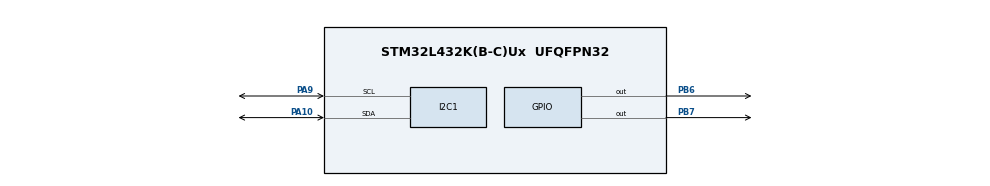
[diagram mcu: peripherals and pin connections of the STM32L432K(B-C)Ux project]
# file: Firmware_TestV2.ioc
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Mcu.Family=STM32L4
Mcu.Name=STM32L432K(B-C)Ux
Mcu.Package=UFQFPN32
NVIC.PriorityGroup=NVIC_PRIORITYGROUP_4
NVIC.TIM6_DAC_IRQn=true\:0\:0\:false\:false\:true\:true\:true
PA10.Mode=I2C
PA10.Signal=I2C1_SDA
PA13\ (JTMS-SWDIO).Mode=Trace_Asynchronous_SW
PA13\ (JTMS-SWDIO).Signal=SYS_JTMS-SWDIO
PA14\ (JTCK-SWCLK).Mode=Trace_Asynchronous_SW
PA14\ (JTCK-SWCLK).Signal=SYS_JTCK-SWCLK
PA9.Mode=I2C
PA9.Signal=I2C1_SCL
PB3\ (JTDO-TRACESWO).Mode=Trace_Asynchronous_SW
PB3\ (JTDO-TRACESWO).Signal=SYS_JTDO-SWO
PB6.Signal=GPIO_Output
PB7.Signal=GPIO_Output
ProjectManager.HeapSize=0x200
ProjectManager.StackSize=0x400
ProjectManager.TargetToolchain=STM32CubeIDE
RCC.HSE_VALUE=8000000
RCC.HSI48_VALUE=48000000
RCC.HSI_VALUE=16000000
RCC.LSE_VALUE=32768
RCC.MSI_VALUE=4000000
RCC.VCOOutputFreq_Value=32000000
TIM6.Period=5000-1
TIM6.Prescaler=800-1
VP_TIM6_VS_ClockSourceINT.Mode=Enable_Timer
board=custom

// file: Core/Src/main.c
/* USER CODE BEGIN Header */
/**
  ******************************************************************************
  * @file           : main.c
  * @brief          : Main program body
  ******************************************************************************
  * @attention
  *
  * <h2><center>&copy; Copyright (c) 2021 STMicroelectronics.
  * All rights reserved.</center></h2>
  *
  * This software component is licensed by ST under BSD 3-Clause license,
  * the "License"; You may not use this file except in compliance with the
  * License. You may obtain a copy of the License at:
  *                        opensource.org/licenses/BSD-3-Clause
  *
  ******************************************************************************
  */
/* USER CODE END Header */
#include "main.h"

/* USER CODE BEGIN Includes */
#include "math.h"
#include "BQ76930.h"
//#include "bq76930_func.h"
//#include "registers.h"
/* USER CODE END Includes */

/* USER CODE BEGIN PD */
void readADCGAIN();
void readVoltage();
/* USER CODE END PD */

I2C_HandleTypeDef hi2c1;	// STM HAL I2C handler
TIM_HandleTypeDef htim6;	// STM HAL timer handler

void SystemClock_Config(void);
static void MX_GPIO_Init(void);
static void MX_I2C1_Init(void);
static void MX_TIM6_Init(void);

int main(void)
{
  /* USER CODE BEGIN 1 */
	HAL_StatusTypeDef ret;
  /* USER CODE END 1 */

  /* MCU Configuration--------------------------------------------------------*/

  /* Reset of all peripherals, Initializes the Flash interface and the Systick. */
  HAL_Init();

  /* USER CODE BEGIN Init */
  uint8_t data;
  /* USER CODE END Init */

  /* Configure the system clock */
  SystemClock_Config();

  /* Initialize all configured peripherals */
  MX_GPIO_Init();
  MX_I2C1_Init();
  MX_TIM6_Init();
  /* USER CODE BEGIN 2 */
  HAL_TIM_Base_Start_IT(&htim6);	//start timer
  LVBatLiPo dev;

  BQ76930_Initialise(&dev, &hi2c1);	//init device

  /* USER CODE END 2 */

  /* Infinite loop */
  while (1)
  {

  }
}

void SystemClock_Config(void)
{
  RCC_OscInitTypeDef RCC_OscInitStruct = {0};
  RCC_ClkInitTypeDef RCC_ClkInitStruct = {0};
  RCC_PeriphCLKInitTypeDef PeriphClkInit = {0};

  /** Initializes the RCC Oscillators according to the specified parameters
  * in the RCC_OscInitTypeDef structure.
  */
  RCC_OscInitStruct.OscillatorType = RCC_OSCILLATORTYPE_MSI;
  RCC_OscInitStruct.MSIState = RCC_MSI_ON;
  RCC_OscInitStruct.MSICalibrationValue = 0;
  RCC_OscInitStruct.MSIClockRange = RCC_MSIRANGE_6;
  RCC_OscInitStruct.PLL.PLLState = RCC_PLL_NONE;
  if (HAL_RCC_OscConfig(&RCC_OscInitStruct) != HAL_OK)
  {
    Error_Handler();
  }
  /** Initializes the CPU, AHB and APB buses clocks
  */
  RCC_ClkInitStruct.ClockType = RCC_CLOCKTYPE_HCLK|RCC_CLOCKTYPE_SYSCLK
                              |RCC_CLOCKTYPE_PCLK1|RCC_CLOCKTYPE_PCLK2;
  RCC_ClkInitStruct.SYSCLKSource = RCC_SYSCLKSOURCE_MSI;
  RCC_ClkInitStruct.AHBCLKDivider = RCC_SYSCLK_DIV1;
  RCC_ClkInitStruct.APB1CLKDivider = RCC_HCLK_DIV1;
  RCC_ClkInitStruct.APB2CLKDivider = RCC_HCLK_DIV1;

  if (HAL_RCC_ClockConfig(&RCC_ClkInitStruct, FLASH_LATENCY_0) != HAL_OK)
  {
    Error_Handler();
  }
  PeriphClkInit.PeriphClockSelection = RCC_PERIPHCLK_I2C1;
  PeriphClkInit.I2c1ClockSelection = RCC_I2C1CLKSOURCE_PCLK1;
  if (HAL_RCCEx_PeriphCLKConfig(&PeriphClkInit) != HAL_OK)
  {
    Error_Handler();
  }
  /** Configure the main internal regulator output voltage
  */
  if (HAL_PWREx_ControlVoltageScaling(PWR_REGULATOR_VOLTAGE_SCALE1) != HAL_OK)
  {
    Error_Handler();
  }
}

static void MX_I2C1_Init(void)
{

  hi2c1.Instance = I2C1;
  hi2c1.Init.Timing = 0x00000E14;
  hi2c1.Init.OwnAddress1 = 0;
  hi2c1.Init.AddressingMode = I2C_ADDRESSINGMODE_7BIT;
  hi2c1.Init.DualAddressMode = I2C_DUALADDRESS_DISABLE;
  hi2c1.Init.OwnAddress2 = 0;
  hi2c1.Init.OwnAddress2Masks = I2C_OA2_NOMASK;
  hi2c1.Init.GeneralCallMode = I2C_GENERALCALL_DISABLE;
  hi2c1.Init.NoStretchMode = I2C_NOSTRETCH_DISABLE;
  if (HAL_I2C_Init(&hi2c1) != HAL_OK)
  {
    Error_Handler();
  }
  /** Configure Analogue filter
  */
  if (HAL_I2CEx_ConfigAnalogFilter(&hi2c1, I2C_ANALOGFILTER_ENABLE) != HAL_OK)
  {
    Error_Handler();
  }
  /** Configure Digital filter
  */
  if (HAL_I2CEx_ConfigDigitalFilter(&hi2c1, 0) != HAL_OK)
  {
    Error_Handler();
  }

}

static void MX_TIM6_Init(void)
{

  TIM_MasterConfigTypeDef sMasterConfig = {0};

  htim6.Instance = TIM6;
  htim6.Init.Prescaler = 800-1;
  htim6.Init.CounterMode = TIM_COUNTERMODE_UP;
  htim6.Init.Period = 5000-1;
  htim6.Init.AutoReloadPreload = TIM_AUTORELOAD_PRELOAD_DISABLE;
  if (HAL_TIM_Base_Init(&htim6) != HAL_OK)
  {
    Error_Handler();
  }
  sMasterConfig.MasterOutputTrigger = TIM_TRGO_RESET;
  sMasterConfig.MasterSlaveMode = TIM_MASTERSLAVEMODE_DISABLE;
  if (HAL_TIMEx_MasterConfigSynchronization(&htim6, &sMasterConfig) != HAL_OK)
  {
    Error_Handler();
  }

}

static void MX_GPIO_Init(void)
{
  GPIO_InitTypeDef GPIO_InitStruct = {0};

  /* GPIO Ports Clock Enable */
  __HAL_RCC_GPIOA_CLK_ENABLE();
  __HAL_RCC_GPIOB_CLK_ENABLE();

  /*Configure GPIO pin Output Level */
  HAL_GPIO_WritePin(GPIOB, GPIO_PIN_6|GPIO_PIN_7, GPIO_PIN_RESET);

  /*Configure GPIO pins : PB6 PB7 */
  GPIO_InitStruct.Pin = GPIO_PIN_6|GPIO_PIN_7;
  GPIO_InitStruct.Mode = GPIO_MODE_OUTPUT_PP;
  GPIO_InitStruct.Pull = GPIO_NOPULL;
  GPIO_InitStruct.Speed = GPIO_SPEED_FREQ_LOW;
  HAL_GPIO_Init(GPIOB, &GPIO_InitStruct);

}

/* USER CODE BEGIN 4 */
void HAL_TIM_PeriodElapsedCallback(TIM_HandleTypeDef *htim)
{
	if (htim == &htim6)
	{
		HAL_GPIO_TogglePin(GPIOB, GPIO_PIN_7);
	}
}
/* USER CODE END 4 */

void Error_Handler(void)
{
}

/************************ (C) COPYRIGHT STMicroelectronics *****END OF FILE****/
